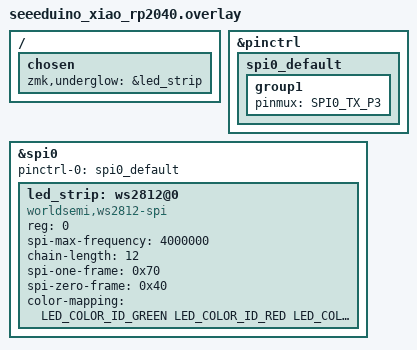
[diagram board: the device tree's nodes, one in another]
#include <dt-bindings/led/led.h>

/*
 * Antari on XIAO RP2040: WS2812 x12 driven via SPI0.
 * GP3 (the D10 pad, the PCB's LED data line) is SPI0 TX on the RP2040,
 * so the strip hangs off the SPI peripheral just like on the nRF board.
 */

&pinctrl {
    spi0_default: spi0_default {
        group1 {
            pinmux = <SPI0_TX_P3>;
        };
    };
};

&spi0 {
    status = "okay";
    pinctrl-0 = <&spi0_default>;
    pinctrl-names = "default";

    led_strip: ws2812@0 {
        compatible = "worldsemi,ws2812-spi";
        reg = <0>;
        spi-max-frequency = <4000000>;
        chain-length = <12>;
        spi-one-frame = <0x70>;
        spi-zero-frame = <0x40>;
        color-mapping = <LED_COLOR_ID_GREEN LED_COLOR_ID_RED LED_COLOR_ID_BLUE>;
    };
};

/ {
    chosen {
        zmk,underglow = &led_strip;
    };
};
